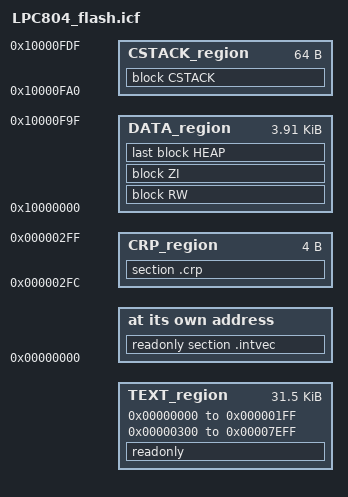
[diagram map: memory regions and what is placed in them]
/*
** ###################################################################
**     Processors:          LPC804M101JDH20
**                          LPC804M101JDH24
**                          LPC804M101JHI33
**                          LPC804M111JDH24
**                          LPC804UK
**
**     Compiler:            IAR ANSI C/C++ Compiler for ARM
**     Reference manual:    LPC804 User manual Rev.1.0  24 Jan 2018
**     Version:             rev. 1.0, 2018-01-09
**     Build:               b200408
**
**     Abstract:
**         Linker file for the IAR ANSI C/C++ Compiler for ARM
**
**     Copyright 2016 Freescale Semiconductor, Inc.
**     Copyright 2016-2020 NXP
**     All rights reserved.
**
**     SPDX-License-Identifier: BSD-3-Clause
**
**     http:                 www.nxp.com
**     mail:                 support@nxp.com
**
** ###################################################################
*/


/* Stack and Heap Sizes */
if (isdefinedsymbol(__stack_size__)) {
  define symbol __size_cstack__        = __stack_size__;
} else {
  define symbol __size_cstack__        = 0x040;
}

if (isdefinedsymbol(__heap_size__)) {
  define symbol __size_heap__          = __heap_size__;
} else {
  define symbol __size_heap__          = 0x040;
}

define symbol m_interrupts_start               = 0x00000000;
define symbol m_interrupts_end                 = 0x000001FF;

define symbol m_crp_start                      = 0x000002FC;
define symbol m_crp_end                        = 0x000002FF;

define symbol m_text_start                     = 0x00000300;
define symbol m_text_end                       = 0x00007EFF;

define symbol m_data_start                     = 0x10000000;
define symbol m_data_end                       = 0x10000FDF - __size_cstack__;

define symbol m_stack_start                    = 0x10000FE0 - __size_cstack__;
define symbol m_stack_end                      = 0x10000FDF;

define memory mem with size = 4G;

define region TEXT_region             = mem:[from m_interrupts_start to m_interrupts_end]
                                      | mem:[from m_text_start to m_text_end];
define region DATA_region             = mem:[from m_data_start to m_stack_start - 1];
define region CSTACK_region           = mem:[from m_stack_start to m_stack_end];
define region CRP_region              = mem:[from  m_crp_start to m_crp_end];

define block CSTACK    with alignment = 8, size = __size_cstack__   { };
define block HEAP      with alignment = 8, size = __size_heap__     { };
define block RW        { readwrite };
define block ZI        { zi };

initialize by copy { readwrite, section .textrw };

if (isdefinedsymbol(__USE_DLIB_PERTHREAD))
{
  /* Required in a multi-threaded application */
  initialize by copy with packing = none { section __DLIB_PERTHREAD };
}

do not initialize  { section .noinit };

place at address mem: m_interrupts_start    { readonly section .intvec };
place in TEXT_region                        { readonly };
place in DATA_region                        { block RW };
place in DATA_region                        { block ZI };
place in DATA_region                        { last block HEAP };
place in CSTACK_region                      { block CSTACK };
place in CRP_region                         { section .crp };
